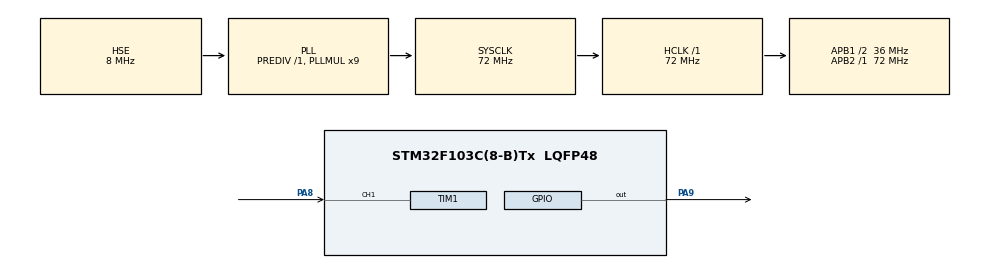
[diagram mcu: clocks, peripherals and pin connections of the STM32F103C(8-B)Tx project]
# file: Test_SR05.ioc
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Mcu.Family=STM32F1
Mcu.Name=STM32F103C(8-B)Tx
Mcu.Package=LQFP48
NVIC.PriorityGroup=NVIC_PRIORITYGROUP_4
NVIC.TIM1_CC_IRQn=true\:0\:0\:false\:false\:true\:true\:true\:true
PA8.Signal=S_TIM1_CH1
PA9.Signal=GPIO_Output
PD0-OSC_IN.Mode=HSE-External-Oscillator
PD0-OSC_IN.Signal=RCC_OSC_IN
PD1-OSC_OUT.Mode=HSE-External-Oscillator
PD1-OSC_OUT.Signal=RCC_OSC_OUT
ProjectManager.HeapSize=0x200
ProjectManager.StackSize=0x400
ProjectManager.TargetToolchain=MDK-ARM V5.32
RCC.AHBFreq_Value=72000000
RCC.APB1CLKDivider=RCC_HCLK_DIV2
RCC.APB1Freq_Value=36000000
RCC.APB1TimFreq_Value=72000000
RCC.APB2Freq_Value=72000000
RCC.APB2TimFreq_Value=72000000
RCC.HCLKFreq_Value=72000000
RCC.PLLMUL=RCC_PLL_MUL9
RCC.PLLSourceVirtual=RCC_PLLSOURCE_HSE
RCC.SYSCLKFreq_VALUE=72000000
RCC.SYSCLKSource=RCC_SYSCLKSOURCE_PLLCLK
RCC.USBFreq_Value=72000000
SH.S_TIM1_CH1.0=TIM1_CH1,Input_Capture1_from_TI1
TIM1.Channel-Input_Capture1_from_TI1=TIM_CHANNEL_1
TIM1.Period=0xffff-1
TIM1.Prescaler=72-1
VP_SYS_VS_ND.Mode=No_Debug
VP_TIM1_VS_ClockSourceINT.Mode=Internal
board=custom

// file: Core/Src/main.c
/* USER CODE BEGIN Header */
/**
  ******************************************************************************
  * @file           : main.c
  * @brief          : Main program body
  ******************************************************************************
  * @attention
  *
  * Copyright (c) 2023 STMicroelectronics.
  * All rights reserved.
  *
  * This software is licensed under terms that can be found in the LICENSE file
  * in the root directory of this software component.
  * If no LICENSE file comes with this software, it is provided AS-IS.
  *
  ******************************************************************************
  */
/* USER CODE END Header */
#include "main.h"

TIM_HandleTypeDef htim1;

void SystemClock_Config(void);
static void MX_GPIO_Init(void);
static void MX_TIM1_Init(void);

void delay (uint16_t time)
{
	__HAL_TIM_SET_COUNTER(&htim1, 0);
	while (__HAL_TIM_GET_COUNTER (&htim1) < time);
}

uint32_t IC_Val1 = 0;
uint32_t IC_Val2 = 0;
uint32_t Difference = 0;
uint8_t Is_First_Captured = 0;  // is the first value captured ?
uint8_t Distance  = 0;
char dist[10];

#define TRIG_PIN GPIO_PIN_9
#define TRIG_PORT GPIOA

// Let's write the callback function

void HAL_TIM_IC_CaptureCallback(TIM_HandleTypeDef *htim)
{
	if (htim->Channel == HAL_TIM_ACTIVE_CHANNEL_1)  // if the interrupt source is channel1
	{
		if (Is_First_Captured==0) // if the first value is not captured
		{
			IC_Val1 = HAL_TIM_ReadCapturedValue(htim, TIM_CHANNEL_1); // read the first value
			Is_First_Captured = 1;  // set the first captured as true
			// Now change the polarity to falling edge
			__HAL_TIM_SET_CAPTUREPOLARITY(htim, TIM_CHANNEL_1, TIM_INPUTCHANNELPOLARITY_FALLING);
		}

		else if (Is_First_Captured==1)   // if the first is already captured
		{
			IC_Val2 = HAL_TIM_ReadCapturedValue(htim, TIM_CHANNEL_1);  // read second value
			__HAL_TIM_SET_COUNTER(htim, 0);  // reset the counter

			if (IC_Val2 > IC_Val1)
			{
				Difference = IC_Val2-IC_Val1;
			}

			else if (IC_Val1 > IC_Val2)
			{
				Difference = (0xffff - IC_Val1) + IC_Val2;
			}

			Distance = Difference * .034/2;
			Is_First_Captured = 0; // set it back to false

			// set polarity to rising edge
			__HAL_TIM_SET_CAPTUREPOLARITY(htim, TIM_CHANNEL_1, TIM_INPUTCHANNELPOLARITY_RISING);
			__HAL_TIM_DISABLE_IT(&htim1, TIM_IT_CC1);
		}
	}
}

uint8_t HCSR04_Read (void)
{
	HAL_GPIO_WritePin(TRIG_PORT, TRIG_PIN, GPIO_PIN_SET);  // pull the TRIG pin HIGH
	delay(10);  // wait for 10 us
	HAL_GPIO_WritePin(TRIG_PORT, TRIG_PIN, GPIO_PIN_RESET);  // pull the TRIG pin low

	__HAL_TIM_ENABLE_IT(&htim1, TIM_IT_CC1);
	return Distance;
}

int main(void)
{

  /* MCU Configuration--------------------------------------------------------*/

  /* Reset of all peripherals, Initializes the Flash interface and the Systick. */
  HAL_Init();

  /* Configure the system clock */
  SystemClock_Config();

  /* Initialize all configured peripherals */
  MX_GPIO_Init();
  MX_TIM1_Init();
 HAL_TIM_IC_Start_IT(&htim1, TIM_CHANNEL_1);
  /* Infinite loop */
  /* USER CODE BEGIN WHILE */
  while (1)
  {
		HCSR04_Read();
		//sprintf(dist," %d", Distance);
	  HAL_Delay(500);
    /* USER CODE END WHILE */

  }
}

void SystemClock_Config(void)
{
  RCC_OscInitTypeDef RCC_OscInitStruct = {0};
  RCC_ClkInitTypeDef RCC_ClkInitStruct = {0};

  /** Initializes the RCC Oscillators according to the specified parameters
  * in the RCC_OscInitTypeDef structure.
  */
  RCC_OscInitStruct.OscillatorType = RCC_OSCILLATORTYPE_HSE;
  RCC_OscInitStruct.HSEState = RCC_HSE_ON;
  RCC_OscInitStruct.HSEPredivValue = RCC_HSE_PREDIV_DIV1;
  RCC_OscInitStruct.HSIState = RCC_HSI_ON;
  RCC_OscInitStruct.PLL.PLLState = RCC_PLL_ON;
  RCC_OscInitStruct.PLL.PLLSource = RCC_PLLSOURCE_HSE;
  RCC_OscInitStruct.PLL.PLLMUL = RCC_PLL_MUL9;
  if (HAL_RCC_OscConfig(&RCC_OscInitStruct) != HAL_OK)
  {
    Error_Handler();
  }

  /** Initializes the CPU, AHB and APB buses clocks
  */
  RCC_ClkInitStruct.ClockType = RCC_CLOCKTYPE_HCLK|RCC_CLOCKTYPE_SYSCLK
                              |RCC_CLOCKTYPE_PCLK1|RCC_CLOCKTYPE_PCLK2;
  RCC_ClkInitStruct.SYSCLKSource = RCC_SYSCLKSOURCE_PLLCLK;
  RCC_ClkInitStruct.AHBCLKDivider = RCC_SYSCLK_DIV1;
  RCC_ClkInitStruct.APB1CLKDivider = RCC_HCLK_DIV2;
  RCC_ClkInitStruct.APB2CLKDivider = RCC_HCLK_DIV1;

  if (HAL_RCC_ClockConfig(&RCC_ClkInitStruct, FLASH_LATENCY_2) != HAL_OK)
  {
    Error_Handler();
  }
}

static void MX_TIM1_Init(void)
{

  TIM_ClockConfigTypeDef sClockSourceConfig = {0};
  TIM_MasterConfigTypeDef sMasterConfig = {0};
  TIM_IC_InitTypeDef sConfigIC = {0};

  htim1.Instance = TIM1;
  htim1.Init.Prescaler = 72-1;
  htim1.Init.CounterMode = TIM_COUNTERMODE_UP;
  htim1.Init.Period = 0xffff-1;
  htim1.Init.ClockDivision = TIM_CLOCKDIVISION_DIV1;
  htim1.Init.RepetitionCounter = 0;
  htim1.Init.AutoReloadPreload = TIM_AUTORELOAD_PRELOAD_DISABLE;
  if (HAL_TIM_Base_Init(&htim1) != HAL_OK)
  {
    Error_Handler();
  }
  sClockSourceConfig.ClockSource = TIM_CLOCKSOURCE_INTERNAL;
  if (HAL_TIM_ConfigClockSource(&htim1, &sClockSourceConfig) != HAL_OK)
  {
    Error_Handler();
  }
  if (HAL_TIM_IC_Init(&htim1) != HAL_OK)
  {
    Error_Handler();
  }
  sMasterConfig.MasterOutputTrigger = TIM_TRGO_RESET;
  sMasterConfig.MasterSlaveMode = TIM_MASTERSLAVEMODE_DISABLE;
  if (HAL_TIMEx_MasterConfigSynchronization(&htim1, &sMasterConfig) != HAL_OK)
  {
    Error_Handler();
  }
  sConfigIC.ICPolarity = TIM_INPUTCHANNELPOLARITY_RISING;
  sConfigIC.ICSelection = TIM_ICSELECTION_DIRECTTI;
  sConfigIC.ICPrescaler = TIM_ICPSC_DIV1;
  sConfigIC.ICFilter = 0;
  if (HAL_TIM_IC_ConfigChannel(&htim1, &sConfigIC, TIM_CHANNEL_1) != HAL_OK)
  {
    Error_Handler();
  }

}

static void MX_GPIO_Init(void)
{
  GPIO_InitTypeDef GPIO_InitStruct = {0};

  /* GPIO Ports Clock Enable */
  __HAL_RCC_GPIOD_CLK_ENABLE();
  __HAL_RCC_GPIOA_CLK_ENABLE();

  /*Configure GPIO pin Output Level */
  HAL_GPIO_WritePin(GPIOA, GPIO_PIN_9, GPIO_PIN_RESET);

  /*Configure GPIO pin : PA9 */
  GPIO_InitStruct.Pin = GPIO_PIN_9;
  GPIO_InitStruct.Mode = GPIO_MODE_OUTPUT_PP;
  GPIO_InitStruct.Pull = GPIO_NOPULL;
  GPIO_InitStruct.Speed = GPIO_SPEED_FREQ_LOW;
  HAL_GPIO_Init(GPIOA, &GPIO_InitStruct);

}

void Error_Handler(void)
{
  __disable_irq();
  while (1)
  {
  }
}
